AUTOSAR XML (schema 4-2-2)
package /ComponentTypes
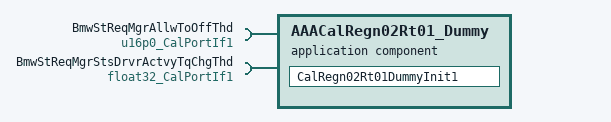
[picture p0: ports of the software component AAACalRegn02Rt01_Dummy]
  application sw component type AAACalRegn02Rt01_Dummy
    require port BmwStReqMgrAllwToOffThd: parameter-require-com-spec{init-value=500, parameter=Val}, required-interface=u16p0_CalPortIf1
    require port BmwStReqMgrStsDrvrActvyTqChgThd: parameter-require-com-spec{init-value=0.2, parameter=Val}, required-interface=float32_CalPortIf1
    behavior AAACalRegn02Rt01_Dummy_InternalBehavior: supports-multiple-instantiation=true
      init event AAACalRegn02Rt01_Dummy_InitEvent: start-on-event=CalRegn02Rt01DummyInit1
      runnable CalRegn02Rt01DummyInit1
  swc implementation AAACalRegn02Rt00_Dummy_Implementation: behavior=AAACalRegn02Rt01_Dummy_InternalBehavior
    code-descriptors:
      code Default: artifact-descriptors=autosar-engineering-object={short-label=Default, category=SWSRC}
